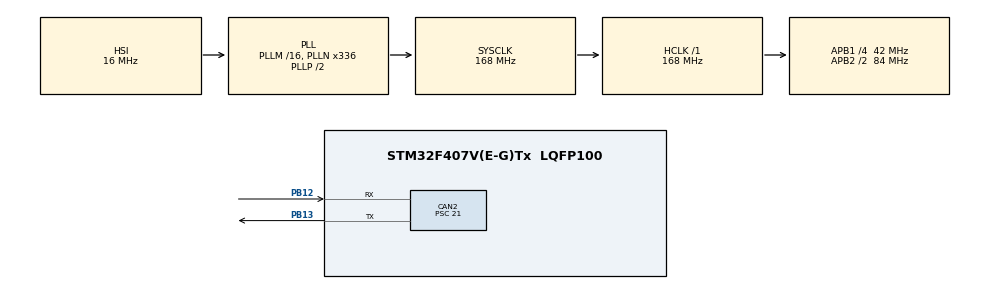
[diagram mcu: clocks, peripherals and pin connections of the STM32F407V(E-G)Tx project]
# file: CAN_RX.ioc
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CAN2.BS1=CAN_BS1_13TQ
CAN2.BS2=CAN_BS2_2TQ
CAN2.CalculateBaudRate=125000
CAN2.CalculateTimeBit=8000
CAN2.CalculateTimeQuantum=500.0
CAN2.NART=ENABLE
CAN2.Prescaler=21
Mcu.Family=STM32F4
Mcu.Name=STM32F407V(E-G)Tx
Mcu.Package=LQFP100
NVIC.CAN2_RX0_IRQn=true\:0\:0\:false\:true\:true\:1\:true\:true\:true
NVIC.PriorityGroup=NVIC_PRIORITYGROUP_4
PB12.Mode=CAN_Activate
PB12.Signal=CAN2_RX
PB13.Mode=CAN_Activate
PB13.Signal=CAN2_TX
ProjectManager.HeapSize=0x200
ProjectManager.StackSize=0x400
ProjectManager.TargetToolchain=STM32CubeIDE
RCC.48MHZClocksFreq_Value=84000000
RCC.AHBFreq_Value=168000000
RCC.APB1CLKDivider=RCC_HCLK_DIV4
RCC.APB1Freq_Value=42000000
RCC.APB1TimFreq_Value=84000000
RCC.APB2CLKDivider=RCC_HCLK_DIV2
RCC.APB2Freq_Value=84000000
RCC.APB2TimFreq_Value=168000000
RCC.CortexFreq_Value=168000000
RCC.HCLKFreq_Value=168000000
RCC.HSE_VALUE=25000000
RCC.HSI_VALUE=16000000
RCC.LSE_VALUE=32768
RCC.PLLN=336
RCC.SYSCLKFreq_VALUE=168000000
RCC.SYSCLKSource=RCC_SYSCLKSOURCE_PLLCLK
RCC.VCOOutputFreq_Value=336000000
board=custom

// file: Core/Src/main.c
/* USER CODE BEGIN Header */
/**
  ******************************************************************************
  * @file           : main.c
  * @brief          : Main program body
  ******************************************************************************
  * @attention
  *
  * Copyright (c) 2023 STMicroelectronics.
  * All rights reserved.
  *
  * This software is licensed under terms that can be found in the LICENSE file
  * in the root directory of this software component.
  * If no LICENSE file comes with this software, it is provided AS-IS.
  *
  ******************************************************************************
  */
/* USER CODE END Header */
#include "main.h"

CAN_HandleTypeDef hcan2;

/* USER CODE BEGIN PV */
CAN_FilterTypeDef  sFilterConfig;   // ?��?�� ?��?�� 구조�??? �????��
CAN_RxHeaderTypeDef   RxHeader;
uint8_t               RxData[8];
/* USER CODE END PV */

void SystemClock_Config(void);
static void MX_GPIO_Init(void);
static void MX_CAN2_Init(void);
static void MX_NVIC_Init(void);
/* USER CODE BEGIN PFP */
// CAN ?��?�� ?��?��?��?�� 콜백
void HAL_CAN_RxFifo0MsgPendingCallback(CAN_HandleTypeDef *CanHandle)
{
  /* Get RX message */
  if (HAL_CAN_GetRxMessage(CanHandle, CAN_RX_FIFO0, &RxHeader, RxData) != HAL_OK)
  {
    /* Reception Error */
    Error_Handler();
  }
}

/* USER CODE END PFP */

int main(void)
{

  /* MCU Configuration--------------------------------------------------------*/

  /* Reset of all peripherals, Initializes the Flash interface and the Systick. */
  HAL_Init();

  /* Configure the system clock */
  SystemClock_Config();

  /* Initialize all configured peripherals */
  MX_GPIO_Init();
  MX_CAN2_Init();

  /* Initialize interrupts */
  MX_NVIC_Init();
  /* USER CODE BEGIN 2 */
  /* CAN Filter Init */
  sFilterConfig.FilterBank = 0;
  sFilterConfig.FilterMode = CAN_FILTERMODE_IDMASK;		//0x00000000
  sFilterConfig.FilterScale = CAN_FILTERSCALE_32BIT;	//0x00000001
  sFilterConfig.FilterIdHigh = 0x0000;
  sFilterConfig.FilterIdLow = 0x0000;
  sFilterConfig.FilterMaskIdHigh = 0x0000;              // 0x00000000 = 모든 ID를 수신받는다.
  sFilterConfig.FilterMaskIdLow = 0x0000;
  sFilterConfig.FilterFIFOAssignment = CAN_RX_FIFO0;	//0x00000000
  sFilterConfig.FilterActivation = ENABLE;
  sFilterConfig.SlaveStartFilterBank = 0;

  if (HAL_CAN_ConfigFilter(&hcan2, &sFilterConfig) != HAL_OK)
  {
    /* Filter configuration Error */
    Error_Handler();
  }

  /* Can Start */
  if (HAL_CAN_Start(&hcan2) != HAL_OK)
  {
    /* Start Error */
    Error_Handler();
  }

  /* Activate CAN RX notification */
  if (HAL_CAN_ActivateNotification(&hcan2, CAN_IT_RX_FIFO0_MSG_PENDING) != HAL_OK)
  {
    /* Notification Error */
    Error_Handler();
  }
  /* USER CODE END 2 */

  /* Infinite loop */
  while (1)
  {

  }
}

void SystemClock_Config(void)
{
  RCC_OscInitTypeDef RCC_OscInitStruct = {0};
  RCC_ClkInitTypeDef RCC_ClkInitStruct = {0};

  /** Configure the main internal regulator output voltage
  */
  __HAL_RCC_PWR_CLK_ENABLE();
  __HAL_PWR_VOLTAGESCALING_CONFIG(PWR_REGULATOR_VOLTAGE_SCALE1);

  /** Initializes the RCC Oscillators according to the specified parameters
  * in the RCC_OscInitTypeDef structure.
  */
  RCC_OscInitStruct.OscillatorType = RCC_OSCILLATORTYPE_HSI;
  RCC_OscInitStruct.HSIState = RCC_HSI_ON;
  RCC_OscInitStruct.HSICalibrationValue = RCC_HSICALIBRATION_DEFAULT;
  RCC_OscInitStruct.PLL.PLLState = RCC_PLL_ON;
  RCC_OscInitStruct.PLL.PLLSource = RCC_PLLSOURCE_HSI;
  RCC_OscInitStruct.PLL.PLLM = 16;
  RCC_OscInitStruct.PLL.PLLN = 336;
  RCC_OscInitStruct.PLL.PLLP = RCC_PLLP_DIV2;
  RCC_OscInitStruct.PLL.PLLQ = 4;
  if (HAL_RCC_OscConfig(&RCC_OscInitStruct) != HAL_OK)
  {
    Error_Handler();
  }

  /** Initializes the CPU, AHB and APB buses clocks
  */
  RCC_ClkInitStruct.ClockType = RCC_CLOCKTYPE_HCLK|RCC_CLOCKTYPE_SYSCLK
                              |RCC_CLOCKTYPE_PCLK1|RCC_CLOCKTYPE_PCLK2;
  RCC_ClkInitStruct.SYSCLKSource = RCC_SYSCLKSOURCE_PLLCLK;
  RCC_ClkInitStruct.AHBCLKDivider = RCC_SYSCLK_DIV1;
  RCC_ClkInitStruct.APB1CLKDivider = RCC_HCLK_DIV4;
  RCC_ClkInitStruct.APB2CLKDivider = RCC_HCLK_DIV2;

  if (HAL_RCC_ClockConfig(&RCC_ClkInitStruct, FLASH_LATENCY_5) != HAL_OK)
  {
    Error_Handler();
  }
}

/**
  * @brief NVIC Configuration.
  * @retval None
  */
static void MX_NVIC_Init(void)
{
  /* CAN2_RX0_IRQn interrupt configuration */
  HAL_NVIC_SetPriority(CAN2_RX0_IRQn, 0, 0);
  HAL_NVIC_EnableIRQ(CAN2_RX0_IRQn);
}

static void MX_CAN2_Init(void)
{

  hcan2.Instance = CAN2;
  hcan2.Init.Prescaler = 21;
  hcan2.Init.Mode = CAN_MODE_NORMAL;
  hcan2.Init.SyncJumpWidth = CAN_SJW_1TQ;
  hcan2.Init.TimeSeg1 = CAN_BS1_13TQ;
  hcan2.Init.TimeSeg2 = CAN_BS2_2TQ;
  hcan2.Init.TimeTriggeredMode = DISABLE;
  hcan2.Init.AutoBusOff = DISABLE;
  hcan2.Init.AutoWakeUp = DISABLE;
  hcan2.Init.AutoRetransmission = ENABLE;
  hcan2.Init.ReceiveFifoLocked = DISABLE;
  hcan2.Init.TransmitFifoPriority = DISABLE;
  if (HAL_CAN_Init(&hcan2) != HAL_OK)
  {
    Error_Handler();
  }

}

static void MX_GPIO_Init(void)
{

  /* GPIO Ports Clock Enable */
  __HAL_RCC_GPIOB_CLK_ENABLE();

}

void Error_Handler(void)
{
  __disable_irq();
  while (1)
  {
  }
}
